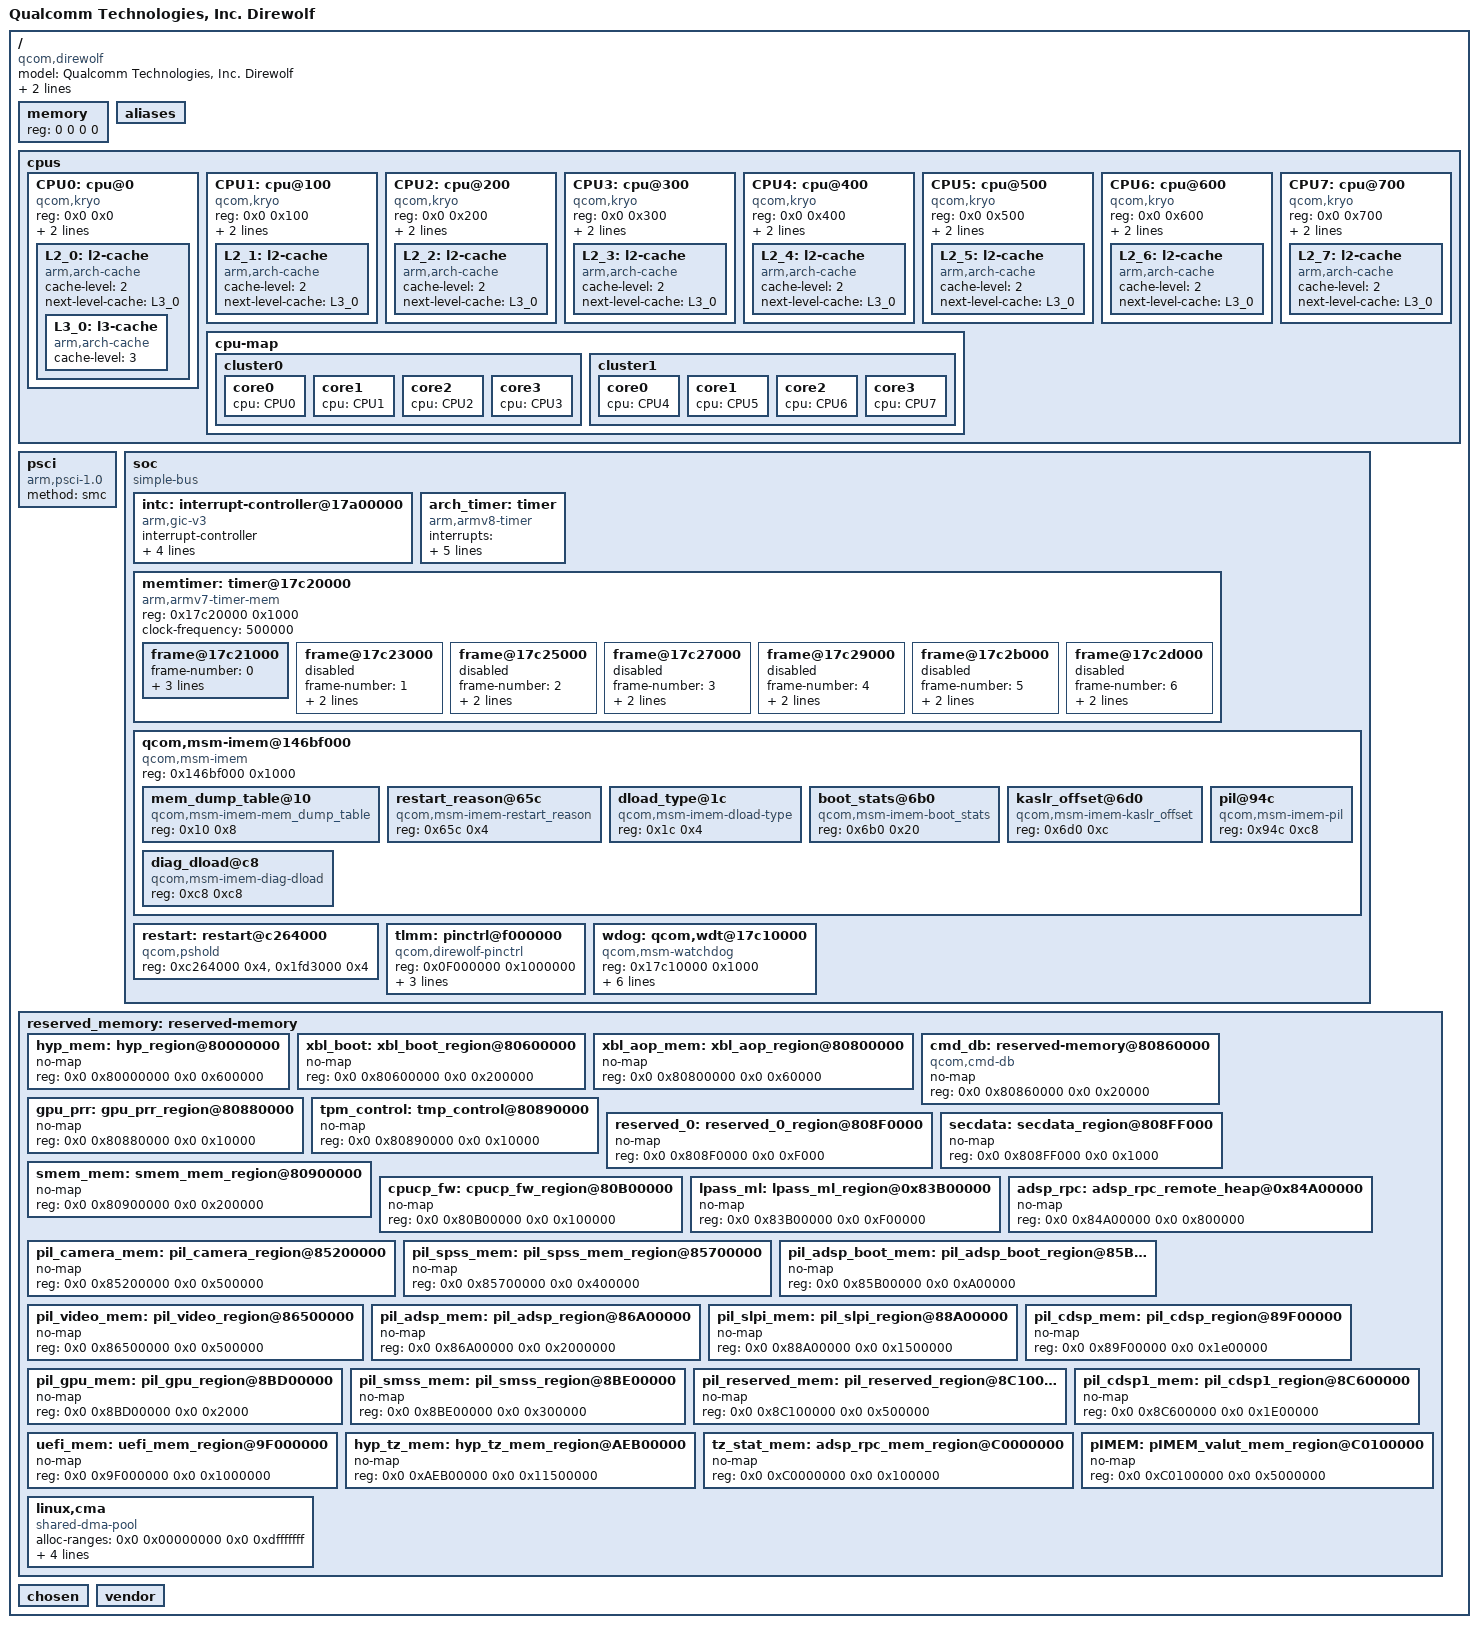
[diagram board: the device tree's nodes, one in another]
#include <dt-bindings/interrupt-controller/arm-gic.h>
#include <dt-bindings/gpio/gpio.h>

/ {
	model = "Qualcomm Technologies, Inc. Direwolf";
	compatible = "qcom,direwolf";
	qcom,msm-name = "Direwolf V1";
	interrupt-parent = <&intc>;

	#address-cells = <2>;
	#size-cells = <2>;
	memory { device_type = "memory"; reg = <0 0 0 0>; };

	aliases { };

	cpus {
		#address-cells = <2>;
		#size-cells = <0>;

		CPU0: cpu@0 {
			device_type = "cpu";
			compatible = "qcom,kryo";
			reg = <0x0 0x0>;
			enable-method = "psci";
			next-level-cache = <&L2_0>;
			L2_0: l2-cache {
				compatible = "arm,arch-cache";
				cache-level = <2>;
				next-level-cache = <&L3_0>;

				L3_0: l3-cache {
					compatible = "arm,arch-cache";
					cache-level = <3>;
				};
			};
		};

		CPU1: cpu@100 {
			device_type = "cpu";
			compatible = "qcom,kryo";
			reg = <0x0 0x100>;
			enable-method = "psci";
			next-level-cache = <&L2_1>;
			L2_1: l2-cache {
			      compatible = "arm,arch-cache";
			      cache-level = <2>;
			      next-level-cache = <&L3_0>;
			};
		};

		CPU2: cpu@200 {
			device_type = "cpu";
			compatible = "qcom,kryo";
			reg = <0x0 0x200>;
			enable-method = "psci";
			next-level-cache = <&L2_2>;
			L2_2: l2-cache {
			      compatible = "arm,arch-cache";
			      cache-level = <2>;
			      next-level-cache = <&L3_0>;
			};
		};

		CPU3: cpu@300 {
			device_type = "cpu";
			compatible = "qcom,kryo";
			reg = <0x0 0x300>;
			enable-method = "psci";
			next-level-cache = <&L2_3>;
			L2_3: l2-cache {
			      compatible = "arm,arch-cache";
			      cache-level = <2>;
			      next-level-cache = <&L3_0>;
			};
		};

		CPU4: cpu@400 {
			device_type = "cpu";
			compatible = "qcom,kryo";
			reg = <0x0 0x400>;
			enable-method = "psci";
			next-level-cache = <&L2_4>;
			L2_4: l2-cache {
			      compatible = "arm,arch-cache";
			      cache-level = <2>;
			      next-level-cache = <&L3_0>;
			};
		};

		CPU5: cpu@500 {
			device_type = "cpu";
			compatible = "qcom,kryo";
			reg = <0x0 0x500>;
			enable-method = "psci";
			next-level-cache = <&L2_5>;
			L2_5: l2-cache {
			      compatible = "arm,arch-cache";
			      cache-level = <2>;
			      next-level-cache = <&L3_0>;
			};
		};

		CPU6: cpu@600 {
			device_type = "cpu";
			compatible = "qcom,kryo";
			reg = <0x0 0x600>;
			enable-method = "psci";
			next-level-cache = <&L2_6>;
			L2_6: l2-cache {
			      compatible = "arm,arch-cache";
			      cache-level = <2>;
			      next-level-cache = <&L3_0>;
			};
		};

		CPU7: cpu@700 {
			device_type = "cpu";
			compatible = "qcom,kryo";
			reg = <0x0 0x700>;
			enable-method = "psci";
			next-level-cache = <&L2_7>;
			L2_7: l2-cache {
			      compatible = "arm,arch-cache";
			      cache-level = <2>;
			      next-level-cache = <&L3_0>;
			};
		};

		cpu-map {
			cluster0 {
				core0 {
					cpu = <&CPU0>;
				};

				core1 {
					cpu = <&CPU1>;
				};

				core2 {
					cpu = <&CPU2>;
				};

				core3 {
					cpu = <&CPU3>;
				};
			};

			cluster1 {
				core0 {
					cpu = <&CPU4>;
				};

				core1 {
					cpu = <&CPU5>;
				};

				core2 {
					cpu = <&CPU6>;
				};

				core3 {
					cpu = <&CPU7>;
				};
			};
		};
	};

	psci {
		compatible = "arm,psci-1.0";
		method = "smc";
	};

	soc: soc { };

	reserved_memory: reserved-memory {
		#address-cells = <2>;
		#size-cells = <2>;
		ranges;

		hyp_mem: hyp_region@80000000 {
			no-map;
			reg = <0x0 0x80000000 0x0 0x600000>;
		};

		xbl_boot: xbl_boot_region@80600000 {
			no-map;
			reg = <0x0 0x80600000 0x0 0x200000>;
		};

		xbl_aop_mem: xbl_aop_region@80800000 {
			no-map;
			reg = <0x0 0x80800000 0x0 0x60000>;
		};

		cmd_db: reserved-memory@80860000 {
			compatible = "qcom,cmd-db";
			no-map;
			reg = <0x0 0x80860000 0x0 0x20000>;
		};

		gpu_prr: gpu_prr_region@80880000 {
			no-map;
			reg = <0x0 0x80880000 0x0 0x10000>;
		};

		tpm_control: tmp_control@80890000 {
			no-map;
			reg = <0x0 0x80890000 0x0 0x10000>;
		};

		reserved_0: reserved_0_region@808F0000 {
			no-map;
			reg = <0x0 0x808F0000 0x0 0xF000>;
		};

		secdata: secdata_region@808FF000 {
			no-map;
			reg = <0x0 0x808FF000 0x0 0x1000>;
		};

		smem_mem: smem_mem_region@80900000 {
			no-map;
			reg = <0x0 0x80900000 0x0 0x200000>;
		};

		cpucp_fw: cpucp_fw_region@80B00000 {
			no-map;
			reg = <0x0 0x80B00000 0x0 0x100000>;
		};

		lpass_ml: lpass_ml_region@0x83B00000 {
			no-map;
			reg = <0x0 0x83B00000 0x0 0xF00000>;
		};

		adsp_rpc: adsp_rpc_remote_heap@0x84A00000 {
			no-map;
			reg = <0x0 0x84A00000 0x0 0x800000>;
		};

		pil_camera_mem: pil_camera_region@85200000 {
			no-map;
			reg = <0x0 0x85200000 0x0 0x500000>;
		};

		pil_spss_mem: pil_spss_mem_region@85700000 {
			no-map;
			reg = <0x0 0x85700000 0x0 0x400000>;
		};

		pil_adsp_boot_mem: pil_adsp_boot_region@85B00000 {
			no-map;
			reg = <0x0 0x85B00000 0x0 0xA00000>;
		};

		pil_video_mem: pil_video_region@86500000 {
			no-map;
			reg = <0x0 0x86500000 0x0 0x500000>;
		};

		pil_adsp_mem: pil_adsp_region@86A00000 {
			no-map;
			reg = <0x0 0x86A00000 0x0 0x2000000>;
		};

		pil_slpi_mem: pil_slpi_region@88A00000 {
			no-map;
			reg = <0x0 0x88A00000 0x0 0x1500000>;
		};

		pil_cdsp_mem: pil_cdsp_region@89F00000 {
			no-map;
			reg = <0x0 0x89F00000 0x0 0x1e00000>;
		};

		pil_gpu_mem: pil_gpu_region@8BD00000 {
			no-map;
			reg = <0x0 0x8BD00000 0x0 0x2000>;
		};

		pil_smss_mem: pil_smss_region@8BE00000 {
			no-map;
			reg = <0x0 0x8BE00000 0x0 0x300000>;
		};

		pil_reserved_mem: pil_reserved_region@8C100000 {
			no-map;
			reg = <0x0 0x8C100000 0x0 0x500000>;
		};

		pil_cdsp1_mem: pil_cdsp1_region@8C600000 {
			no-map;
			reg = <0x0 0x8C600000 0x0 0x1E00000>;
		};

		uefi_mem: uefi_mem_region@9F000000 {
			no-map;
			reg = <0x0 0x9F000000 0x0 0x1000000>;
		};

		hyp_tz_mem: hyp_tz_mem_region@AEB00000 {
			no-map;
			reg = <0x0 0xAEB00000 0x0 0x11500000>;
		};

		tz_stat_mem: adsp_rpc_mem_region@C0000000 {
			no-map;
			reg = <0x0 0xC0000000 0x0 0x100000>;
		};

		pIMEM: pIMEM_valut_mem_region@C0100000 {
			no-map;
			reg = <0x0 0xC0100000 0x0 0x5000000>;
		};

		/* global autoconfigured region for contiguous allocations */
		linux,cma {
			compatible = "shared-dma-pool";
			alloc-ranges = <0x0 0x00000000 0x0 0xdfffffff>;
			reusable;
			alignment = <0x0 0x400000>;
			size = <0x0 0x2000000>;
			linux,cma-default;
		};
	};

	chosen { };

	vendor: vendor { };
};

&soc {
	#address-cells = <1>;
	#size-cells = <1>;
	ranges = <0 0 0 0xffffffff>;
	compatible = "simple-bus";

	intc: interrupt-controller@17a00000 {
		compatible = "arm,gic-v3";
		#interrupt-cells = <3>;
		interrupt-controller;
		#redistributor-regions = <1>;
		redistributor-stride = <0x0 0x20000>;
		reg = <0x17a00000 0x10000>,     /* GICD */
		      <0x17a60000 0x100000>;    /* GICR * 8 */
		interrupts = <GIC_PPI 9 IRQ_TYPE_LEVEL_HIGH>;
	};

	arch_timer: timer {
		compatible = "arm,armv8-timer";
		interrupts = <GIC_PPI 13 (GIC_CPU_MASK_SIMPLE(8) | IRQ_TYPE_LEVEL_LOW)>,
			     <GIC_PPI 14 (GIC_CPU_MASK_SIMPLE(8) | IRQ_TYPE_LEVEL_LOW)>,
			     <GIC_PPI 11 (GIC_CPU_MASK_SIMPLE(8) | IRQ_TYPE_LEVEL_LOW)>,
			     <GIC_PPI 12 (GIC_CPU_MASK_SIMPLE(8) | IRQ_TYPE_LEVEL_LOW)>;
		clock-frequency = <19200000>;
	};

	memtimer: timer@17c20000 {
		#address-cells = <1>;
		#size-cells = <1>;
		ranges;
		compatible = "arm,armv7-timer-mem";
		reg = <0x17c20000 0x1000>;
		clock-frequency = <500000>;

		frame@17c21000 {
			frame-number = <0>;
			interrupts = <GIC_SPI 8 IRQ_TYPE_LEVEL_HIGH>,
				     <GIC_SPI 6 IRQ_TYPE_LEVEL_HIGH>;
			reg = <0x17c21000 0x1000>,
			      <0x17c22000 0x1000>;
		};

		frame@17c23000 {
			frame-number = <1>;
			interrupts = <GIC_SPI 9 IRQ_TYPE_LEVEL_HIGH>;
			reg = <0x17c23000 0x1000>;
			status = "disabled";
		};

		frame@17c25000 {
			frame-number = <2>;
			interrupts = <GIC_SPI 10 IRQ_TYPE_LEVEL_HIGH>;
			reg = <0x17c25000 0x1000>;
			status = "disabled";
		};

		frame@17c27000 {
			frame-number = <3>;
			interrupts = <GIC_SPI 11 IRQ_TYPE_LEVEL_HIGH>;
			reg = <0x17c27000 0x1000>;
			status = "disabled";
		};

		frame@17c29000 {
			frame-number = <4>;
			interrupts = <GIC_SPI 12 IRQ_TYPE_LEVEL_HIGH>;
			reg = <0x17c29000 0x1000>;
			status = "disabled";
		};

		frame@17c2b000 {
			frame-number = <5>;
			interrupts = <GIC_SPI 13 IRQ_TYPE_LEVEL_HIGH>;
			reg = <0x17c2b000 0x1000>;
			status = "disabled";
		};

		frame@17c2d000 {
			frame-number = <6>;
			interrupts = <GIC_SPI 14 IRQ_TYPE_LEVEL_HIGH>;
			reg = <0x17c2d000 0x1000>;
			status = "disabled";
		};
	};

	qcom,msm-imem@146bf000 {
		compatible = "qcom,msm-imem";
		reg = <0x146bf000 0x1000>;
		ranges = <0x0 0x146bf000 0x1000>;
		#address-cells = <1>;
		#size-cells = <1>;

		mem_dump_table@10 {
			compatible = "qcom,msm-imem-mem_dump_table";
			reg = <0x10 0x8>;
		};

		restart_reason@65c {
			compatible = "qcom,msm-imem-restart_reason";
			reg = <0x65c 0x4>;
		};

		dload_type@1c {
			compatible = "qcom,msm-imem-dload-type";
			reg = <0x1c 0x4>;
		};

		boot_stats@6b0 {
			compatible = "qcom,msm-imem-boot_stats";
			reg = <0x6b0 0x20>;
		};

		kaslr_offset@6d0 {
			compatible = "qcom,msm-imem-kaslr_offset";
			reg = <0x6d0 0xc>;
		};

		pil@94c {
			compatible = "qcom,msm-imem-pil";
			reg = <0x94c 0xc8>;
		};

		diag_dload@c8 {
			compatible = "qcom,msm-imem-diag-dload";
			reg = <0xc8 0xc8>;
		};
	};

	restart: restart@c264000 {
		compatible = "qcom,pshold";
		reg = <0xc264000 0x4>, <0x1fd3000 0x4>;
		reg-names = "pshold-base", "tcsr-boot-misc-detect";
	};

	tlmm: pinctrl@f000000 {
		compatible = "qcom,direwolf-pinctrl";
		reg = <0x0F000000 0x1000000>;
		interrupts = <GIC_SPI 208 IRQ_TYPE_LEVEL_HIGH>;
		gpio-controller;
		#gpio-cells = <2>;
		interrupt-controller;
		#interrupt-cells = <2>;
	};

	wdog: qcom,wdt@17c10000 {
		compatible = "qcom,msm-watchdog";
		reg = <0x17c10000 0x1000>;
		reg-names = "wdt-base";
		interrupts = <GIC_SPI 0 IRQ_TYPE_LEVEL_HIGH>,
				<GIC_SPI 1 IRQ_TYPE_LEVEL_HIGH>;
		qcom,bark-time = <11000>;
		qcom,pet-time = <9360>;
		qcom,ipi-ping;
		qcom,wakeup-enable;
	};

};

#include "direwolf-pinctrl.dtsi"
